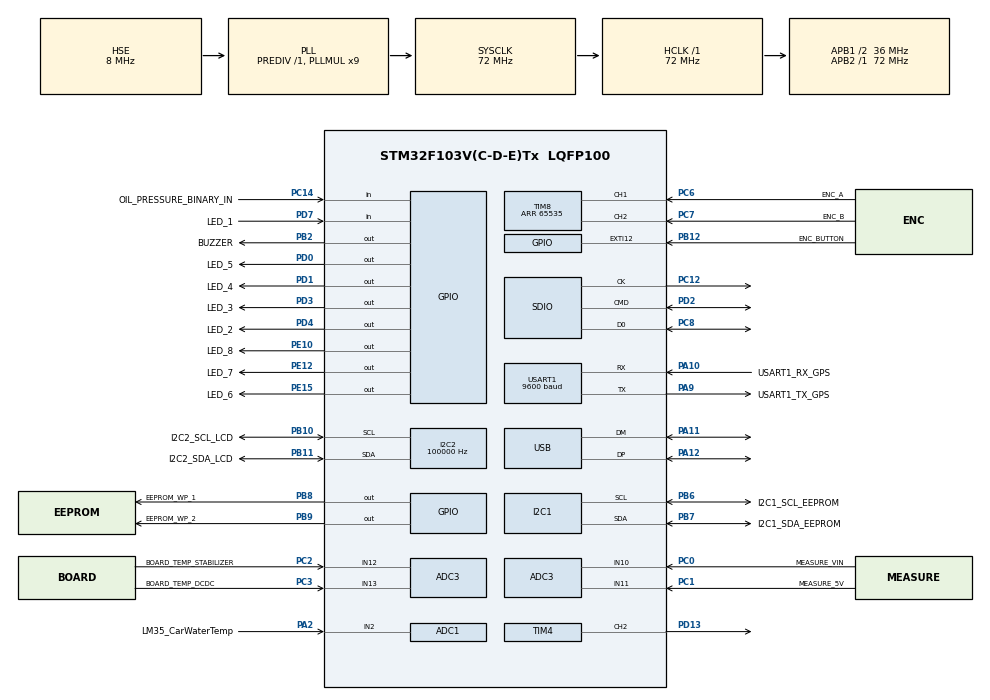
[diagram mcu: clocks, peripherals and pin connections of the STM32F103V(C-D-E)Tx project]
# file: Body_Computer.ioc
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ADC1.Channel-0\#ChannelRegularConversion=ADC_CHANNEL_2
ADC1.ContinuousConvMode=ENABLE
ADC1.NbrOfConversion=1
ADC1.NbrOfConversionFlag=1
ADC1.Rank-0\#ChannelRegularConversion=1
ADC1.SamplingTime-0\#ChannelRegularConversion=ADC_SAMPLETIME_239CYCLES_5
ADC1.master=1
ADC3.Channel-6\#ChannelRegularConversion=ADC_CHANNEL_10
ADC3.Channel-7\#ChannelRegularConversion=ADC_CHANNEL_11
ADC3.Channel-8\#ChannelRegularConversion=ADC_CHANNEL_12
ADC3.Channel-9\#ChannelRegularConversion=ADC_CHANNEL_13
ADC3.ContinuousConvMode=ENABLE
ADC3.DiscontinuousConvMode=DISABLE
ADC3.EnableRegularConversion=ENABLE
ADC3.NbrOfConversion=4
ADC3.NbrOfConversionFlag=1
ADC3.Rank-6\#ChannelRegularConversion=1
ADC3.Rank-7\#ChannelRegularConversion=2
ADC3.Rank-8\#ChannelRegularConversion=3
ADC3.Rank-9\#ChannelRegularConversion=4
ADC3.SamplingTime-6\#ChannelRegularConversion=ADC_SAMPLETIME_239CYCLES_5
ADC3.SamplingTime-7\#ChannelRegularConversion=ADC_SAMPLETIME_239CYCLES_5
ADC3.SamplingTime-8\#ChannelRegularConversion=ADC_SAMPLETIME_239CYCLES_5
ADC3.SamplingTime-9\#ChannelRegularConversion=ADC_SAMPLETIME_239CYCLES_5
Dma.ADC1.3.Direction=DMA_PERIPH_TO_MEMORY
Dma.ADC1.3.Instance=DMA1_Channel1
Dma.ADC1.3.MemDataAlignment=DMA_MDATAALIGN_HALFWORD
Dma.ADC1.3.MemInc=DMA_MINC_ENABLE
Dma.ADC1.3.Mode=DMA_CIRCULAR
Dma.ADC1.3.PeriphDataAlignment=DMA_PDATAALIGN_HALFWORD
Dma.ADC1.3.PeriphInc=DMA_PINC_DISABLE
Dma.ADC1.3.Priority=DMA_PRIORITY_LOW
Dma.ADC3.1.Direction=DMA_PERIPH_TO_MEMORY
Dma.ADC3.1.Instance=DMA2_Channel5
Dma.ADC3.1.MemDataAlignment=DMA_MDATAALIGN_HALFWORD
Dma.ADC3.1.MemInc=DMA_MINC_ENABLE
Dma.ADC3.1.Mode=DMA_CIRCULAR
Dma.ADC3.1.PeriphDataAlignment=DMA_PDATAALIGN_HALFWORD
Dma.ADC3.1.PeriphInc=DMA_PINC_DISABLE
Dma.ADC3.1.Priority=DMA_PRIORITY_LOW
Dma.I2C2_RX.2.Direction=DMA_PERIPH_TO_MEMORY
Dma.I2C2_RX.2.Instance=DMA1_Channel5
Dma.I2C2_RX.2.MemDataAlignment=DMA_MDATAALIGN_BYTE
Dma.I2C2_RX.2.MemInc=DMA_MINC_ENABLE
Dma.I2C2_RX.2.Mode=DMA_NORMAL
Dma.I2C2_RX.2.PeriphDataAlignment=DMA_PDATAALIGN_BYTE
Dma.I2C2_RX.2.PeriphInc=DMA_PINC_DISABLE
Dma.I2C2_RX.2.Priority=DMA_PRIORITY_LOW
Dma.I2C2_TX.0.Direction=DMA_MEMORY_TO_PERIPH
Dma.I2C2_TX.0.Instance=DMA1_Channel4
Dma.I2C2_TX.0.MemDataAlignment=DMA_MDATAALIGN_BYTE
Dma.I2C2_TX.0.MemInc=DMA_MINC_ENABLE
Dma.I2C2_TX.0.Mode=DMA_NORMAL
Dma.I2C2_TX.0.PeriphDataAlignment=DMA_PDATAALIGN_BYTE
Dma.I2C2_TX.0.PeriphInc=DMA_PINC_DISABLE
Dma.I2C2_TX.0.Priority=DMA_PRIORITY_LOW
Dma.Request0=I2C2_TX
Dma.Request1=ADC3
Dma.Request2=I2C2_RX
Dma.Request3=ADC1
FREERTOS.INCLUDE_uxTaskGetStackHighWaterMark=0
FREERTOS.INCLUDE_vTaskDelay=1
FREERTOS.INCLUDE_vTaskDelayUntil=1
FREERTOS.Queues01=Queue_EEPROM_read,5,EEPROM_data_struct,0,Dynamic,NULL,NULL;Queue_EEPROM_write,5,EEPROM_data_struct,0,Dynamic,NULL,NULL;Queue_error_snapshot_dump,5,Error_Code,0,Dynamic,NULL,NULL;Queue_diagnostic_snapshot_dump,5,Diagnostic_Snapshot_struct,0,Dynamic,NULL,NULL
FREERTOS.Tasks01=My_1000ms_Task,0,256,StartTask1000ms,Default,NULL,Dynamic,NULL,NULL;My_500ms_Task,0,128,StartTask500ms,Default,NULL,Dynamic,NULL,NULL;My_LCD_Task,0,512,StartTaskLCD,As external,NULL,Dynamic,NULL,NULL;My_GPS_Task,0,128,StartTaskGPS,As external,NULL,Dynamic,NULL,NULL;My_EEPROM_Task,2,128,StartTaskEEPROM,As external,NULL,Dynamic,NULL,NULL;My_DumpToEEPROM,-1,128,StartTaskDumpToEEPROM,As external,NULL,Dynamic,NULL,NULL;My_DumpToSDCard,-1,1024,StartTaskDumpToSDCard,Default,NULL,Dynamic,NULL,NULL;My_250ms_Task,-3,512,StartTask250ms,Default,NULL,Dynamic,NULL,NULL;My_50ms_Task,-3,128,StartTask50ms,Default,NULL,Dynamic,NULL,NULL;My_DiagCheck,1,256,StartTaskDiagCheck,As external,NULL,Dynamic,NULL,NULL;my_AlarmControl,-3,256,StartTaskAlarmControl,As external,NULL,Dynamic,NULL,NULL
FREERTOS.Timers01=My_Timer_ENC_Button,ENC_Button_LongPress_Callback,osTimerOnce,Default,NULL,Dynamic,NULL;My_Timer_carWaterTempValueCheck,Timer_carWaterTempValueCheck,osTimerOnce,As external,NULL,Dynamic,NULL;My_Timer_carOilTempValueCheck,Timer_carOilTempValueCheck,osTimerOnce,As external,NULL,Dynamic,NULL;My_Timer_carOilAnalogPressureValueCheck,Timer_carOilAnalogPressureValueCheck,osTimerOnce,As external,NULL,Dynamic,NULL;My_Timer_carMainBattVoltageValueCheck,Timer_carMainBattVoltageValueCheck,osTimerOnce,As external,NULL,Dynamic,NULL;My_Timer_carAuxBattVoltageValueCheck,Timer_carAuxBattVoltageValueCheck,osTimerOnce,As external,NULL,Dynamic,NULL;My_Timer_carFuelLevelValueCheck,Timer_carFuelLevelValueCheck,osTimerOnce,As external,NULL,Dynamic,NULL;My_Timer_board3V3VoltageValueCheck,Timer_board3V3VoltageValueCheck,osTimerOnce,As external,NULL,Dynamic,NULL;My_Timer_board5VVoltageValueCheck,Timer_board5VVoltageValueCheck,osTimerOnce,As external,NULL,Dynamic,NULL;My_Timer_boardVinVoltageValueCheck,Timer_boardVinVoltageValueCheck,osTimerOnce,As external,NULL,Dynamic,NULL;My_Timer_board3V3TempValueCheck,Timer_board3V3TempValueCheck,osTimerOnce,As external,NULL,Dynamic,NULL;My_Timer_board5VTempValueCheck,Timer_board5VTempValueCheck,osTimerOnce,As external,NULL,Dynamic,NULL;My_Timer_carOilBinaryPressureValueCheck,Timer_carOilBinaryPressureValueCheck,osTimerOnce,As external,NULL,Dynamic,NULL;My_Timer_Buzzer,Timer_Buzzer,osTimerOnce,As external,NULL,Dynamic,NULL
FREERTOS.configCHECK_FOR_STACK_OVERFLOW=1
FREERTOS.configENABLE_BACKWARD_COMPATIBILITY=0
FREERTOS.configGENERATE_RUN_TIME_STATS=1
FREERTOS.configMAX_PRIORITIES=7
FREERTOS.configRECORD_STACK_HIGH_ADDRESS=1
FREERTOS.configTIMER_QUEUE_LENGTH=40
FREERTOS.configTIMER_TASK_STACK_DEPTH=256
FREERTOS.configTOTAL_HEAP_SIZE=20480
FREERTOS.configUSE_MALLOC_FAILED_HOOK=1
FREERTOS.configUSE_PREEMPTION=1
FREERTOS.configUSE_STATS_FORMATTING_FUNCTIONS=1
FREERTOS.configUSE_TIMERS=1
FREERTOS.configUSE_TRACE_FACILITY=1
I2C1.I2C_Mode=I2C_Standard
I2C1.NoStretchMode=I2C_NOSTRETCH_DISABLE
I2C2.AddressingMode=I2C_ADDRESSINGMODE_7BIT
I2C2.ClockSpeed=100000
I2C2.I2C_Mode=I2C_Standard
Mcu.Family=STM32F1
Mcu.Name=STM32F103V(C-D-E)Tx
Mcu.Package=LQFP100
NVIC.DMA1_Channel1_IRQn=true\:5\:0\:false\:false\:true\:true\:false\:true
NVIC.DMA1_Channel4_IRQn=true\:5\:0\:true\:false\:true\:true\:false\:true
NVIC.DMA1_Channel5_IRQn=true\:5\:0\:true\:false\:true\:true\:false\:true
NVIC.DMA2_Channel4_5_IRQn=true\:5\:0\:false\:false\:true\:true\:false\:true
NVIC.EXTI15_10_IRQn=true\:5\:0\:false\:false\:true\:true\:true\:true
NVIC.I2C1_ER_IRQn=true\:5\:0\:false\:false\:true\:true\:true\:true
NVIC.I2C1_EV_IRQn=true\:5\:0\:false\:false\:true\:true\:true\:true
NVIC.I2C2_ER_IRQn=true\:6\:0\:true\:false\:true\:true\:true\:true
NVIC.I2C2_EV_IRQn=true\:6\:0\:true\:false\:true\:true\:true\:true
NVIC.PriorityGroup=NVIC_PRIORITYGROUP_4
NVIC.TIM6_IRQn=true\:0\:0\:false\:false\:true\:false\:false\:true
NVIC.TIM7_IRQn=true\:5\:0\:false\:false\:true\:true\:true\:true
NVIC.TimeBase=TIM6_IRQn
NVIC.TimeBaseIP=TIM6
NVIC.USART1_IRQn=true\:5\:0\:true\:false\:true\:true\:true\:true
NVIC.USB_LP_CAN1_RX0_IRQn=true\:5\:0\:false\:false\:true\:true\:false\:true
OSC_IN.Mode=HSE-External-Oscillator
OSC_IN.Signal=RCC_OSC_IN
OSC_OUT.Mode=HSE-External-Oscillator
OSC_OUT.Signal=RCC_OSC_OUT
PA10.GPIO_Label=USART1_RX_GPS
PA10.Mode=Asynchronous
PA10.Signal=USART1_RX
PA11.Mode=Device
PA11.Signal=USB_DM
PA12.Mode=Device
PA12.Signal=USB_DP
PA13.Mode=Trace_Asynchronous_SW
PA13.Signal=SYS_JTMS-SWDIO
PA14.Mode=Trace_Asynchronous_SW
PA14.Signal=SYS_JTCK-SWCLK
PA2.GPIO_Label=LM35_CarWaterTemp
PA2.Signal=ADCx_IN2
PA9.GPIO_Label=USART1_TX_GPS
PA9.Mode=Asynchronous
PA9.Signal=USART1_TX
PB10.GPIO_Label=I2C2_SCL_LCD
PB10.Mode=I2C
PB10.Signal=I2C2_SCL
PB11.GPIO_Label=I2C2_SDA_LCD
PB11.Mode=I2C
PB11.Signal=I2C2_SDA
PB12.GPIO_Label=ENC_BUTTON
PB12.GPIO_ModeDefaultEXTI=GPIO_MODE_IT_FALLING
PB12.GPIO_PuPd=GPIO_NOPULL
PB12.Signal=GPXTI12
PB2.GPIO_Label=BUZZER
PB2.GPIO_PuPd=GPIO_PULLDOWN
PB2.Signal=GPIO_Output
PB3.GPIO_Label=SWO
PB3.Mode=Trace_Asynchronous_SW
PB3.Signal=SYS_JTDO-TRACESWO
PB6.GPIO_Label=I2C1_SCL_EEPROM
PB6.Mode=I2C
PB6.Signal=I2C1_SCL
PB7.GPIO_Label=I2C1_SDA_EEPROM
PB7.Mode=I2C
PB7.Signal=I2C1_SDA
PB8.GPIO_Label=EEPROM_WP_1
PB8.GPIO_PuPd=GPIO_PULLDOWN
PB8.Signal=GPIO_Output
PB9.GPIO_Label=EEPROM_WP_2
PB9.GPIO_PuPd=GPIO_PULLDOWN
PB9.Signal=GPIO_Output
PC0.GPIO_Label=MEASURE_VIN
PC0.Signal=ADCx_IN10
PC1.GPIO_Label=MEASURE_5V
PC1.Signal=ADCx_IN11
PC12.Mode=SD_1_bit
PC12.Signal=SDIO_CK
PC14-OSC32_IN.GPIO_Label=OIL_PRESSURE_BINARY_IN
PC14-OSC32_IN.Signal=GPIO_Input
PC2.GPIO_Label=BOARD_TEMP_STABILIZER
PC2.Signal=ADCx_IN12
PC3.GPIO_Label=BOARD_TEMP_DCDC
PC3.Signal=ADCx_IN13
PC6.GPIO_Label=ENC_A
PC6.Signal=S_TIM8_CH1
PC7.GPIO_Label=ENC_B
PC7.Signal=S_TIM8_CH2
PC8.Mode=SD_1_bit
PC8.Signal=SDIO_D0
PD0.GPIO_Label=LED_5
PD0.Signal=GPIO_Output
PD1.GPIO_Label=LED_4
PD1.Signal=GPIO_Output
PD13.Signal=S_TIM4_CH2
PD2.Mode=SD_1_bit
PD2.Signal=SDIO_CMD
PD3.GPIO_Label=LED_3
PD3.Signal=GPIO_Output
PD4.GPIO_Label=LED_2
PD4.Signal=GPIO_Output
PD7.GPIO_Label=LED_1
PD7.Signal=GPIO_Input
PE10.GPIO_Label=LED_8
PE10.Signal=GPIO_Output
PE12.GPIO_Label=LED_7
PE12.Signal=GPIO_Output
PE15.GPIO_Label=LED_6
PE15.Signal=GPIO_Output
ProjectManager.HeapSize=0x400
ProjectManager.StackSize=0x2000
ProjectManager.TargetToolchain=STM32CubeIDE
RCC.ADCPresc=RCC_ADCPCLK2_DIV6
RCC.AHBFreq_Value=72000000
RCC.APB1CLKDivider=RCC_HCLK_DIV2
RCC.APB1Freq_Value=36000000
RCC.APB1TimFreq_Value=72000000
RCC.APB2Freq_Value=72000000
RCC.APB2TimFreq_Value=72000000
RCC.HCLKFreq_Value=72000000
RCC.PLLMUL=RCC_PLL_MUL9
RCC.PLLSourceVirtual=RCC_PLLSOURCE_HSE
RCC.SYSCLKFreq_VALUE=72000000
RCC.SYSCLKSource=RCC_SYSCLKSOURCE_PLLCLK
RCC.USBFreq_Value=48000000
RCC.USBPrescaler=RCC_USBCLKSOURCE_PLL_DIV1_5
SDIO.ClockDiv=18
SH.ADCx_IN10.0=ADC3_IN10,IN10
SH.ADCx_IN11.0=ADC3_IN11,IN11
SH.ADCx_IN12.0=ADC3_IN12,IN12
SH.ADCx_IN13.0=ADC3_IN13,IN13
SH.ADCx_IN2.0=ADC1_IN2,IN2
SH.S_TIM4_CH2.0=TIM4_CH2,PWM Generation2 CH2
SH.S_TIM8_CH1.0=TIM8_CH1,Encoder_Interface
SH.S_TIM8_CH2.0=TIM8_CH2,Encoder_Interface
TIM4.Channel-PWM\ Generation2\ CH2=TIM_CHANNEL_2
TIM4.Period=49
TIM4.Prescaler=71
TIM7.AutoReloadPreload=TIM_AUTORELOAD_PRELOAD_DISABLE
TIM7.Period=99
TIM7.Prescaler=71
TIM8.ClockDivision=TIM_CLOCKDIVISION_DIV1
TIM8.EncoderMode=TIM_ENCODERMODE_TI12
TIM8.IC1Filter=15
TIM8.IC1Prescaler=TIM_ICPSC_DIV1
TIM8.IC2Filter=15
TIM8.IC2Prescaler=TIM_ICPSC_DIV1
TIM8.Period=65535
USART1.BaudRate=9600
USART1.VirtualMode=VM_ASYNC
USB_DEVICE.CLASS_NAME_FS=MSC
USB_DEVICE.USBD_MAX_NUM_CONFIGURATION=2
USB_DEVICE.USBD_MAX_NUM_INTERFACES=2
USB_DEVICE.USBD_SELF_POWERED=0
USB_DEVICE.VirtualMode=Msc
USB_DEVICE.VirtualModeFS=Msc_FS
VP_FATFS_VS_SDIO.Mode=SDIO
VP_FREERTOS_VS_CMSIS_V1.Mode=CMSIS_V1
VP_SYS_VS_tim6.Mode=TIM6
VP_TIM7_VS_ClockSourceINT.Mode=Enable_Timer
VP_USB_DEVICE_VS_USB_DEVICE_MSC_FS.Mode=MSC_FS
board=custom

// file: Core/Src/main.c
/* USER CODE BEGIN Header */
/**
  ******************************************************************************
  * @file           : main.c
  * @brief          : Main program body
  ******************************************************************************
  * @attention
  *
  * <h2><center>&copy; Copyright (c) 2020 STMicroelectronics.
  * All rights reserved.</center></h2>
  *
  * This software component is licensed by ST under BSD 3-Clause license,
  * the "License"; You may not use this file except in compliance with the
  * License. You may obtain a copy of the License at:
  *                        opensource.org/licenses/BSD-3-Clause
  *
  ******************************************************************************
  */
/* USER CODE END Header */
#include "main.h"
#include "cmsis_os.h"
#include "adc.h"
#include "dma.h"
#include "fatfs.h"
#include "i2c.h"
#include "sdio.h"
#include "tim.h"
#include "usart.h"
#include "usb_device.h"
#include "gpio.h"

/* USER CODE BEGIN Includes */

#include "../GPS/GPS_Parsing.h"
#include "../I2C_Workaround/I2C_Workaround.h"
#include "Init_Functions.h"

/* USER CODE END Includes */

/* USER CODE BEGIN PV */
volatile uint32_t licznikShortPresses = 0;
extern ENCButton_struct ENC_button;
extern uint16_t ADC1Measures[NO_OF_ADC1_MEASURES];
extern uint16_t ADC3Measures[NO_OF_ADC3_MEASURES];
extern GPS_data_struct GPS;
//extern LCD_parameters_struct LCD;
extern uint32_t Tim7_Counter_100us;
extern osTimerId My_Timer_ENC_ButtonHandle;

/* USER CODE END PV */

void SystemClock_Config(void);
void MX_FREERTOS_Init(void);
/* USER CODE BEGIN PFP */

void HAL_UART_RxCpltCallback(UART_HandleTypeDef *huart);
void HAL_GPIO_EXTI_Callback(uint16_t GPIO_Pin);

/* USER CODE END PFP */

int main(void)
{
  /* USER CODE BEGIN 1 */
	Error_Code error = NO_ERROR;
  /* USER CODE END 1 */

  /* MCU Configuration--------------------------------------------------------*/

  /* Reset of all peripherals, Initializes the Flash interface and the Systick. */
  HAL_Init();

  /* Configure the system clock */
  SystemClock_Config();

  /* Initialize all configured peripherals */
  MX_GPIO_Init();
  MX_DMA_Init();
  MX_I2C2_Init();
  MX_TIM8_Init();
  MX_ADC3_Init();
  MX_USART1_UART_Init();
  MX_TIM7_Init();
  MX_I2C1_Init();
  MX_TIM4_Init();
  MX_ADC1_Init();
  MX_SDIO_SD_Init();
  MX_FATFS_Init();
  /* USER CODE BEGIN 2 */

  	error = (Error_Code)HAL_TIM_Encoder_Start(&htim8, TIM_CHANNEL_ALL);

	if(NO_ERROR != error)
	{
		error = TIM__ENCODER_START_FAIL;
		my_error_handler(error);
	}

	error = (Error_Code)HAL_ADCEx_Calibration_Start(&hadc1);
	error = (Error_Code)HAL_ADCEx_Calibration_Start(&hadc3);

	if(NO_ERROR != error)
	{
		error = ADC__CALIBRATION_FAIL;
		my_error_handler(error);
	}

	HAL_ADC_Start_DMA(&hadc1, (uint32_t*)ADC1Measures, NO_OF_ADC1_MEASURES);
	HAL_ADC_Start_DMA(&hadc3, (uint32_t*)ADC3Measures, NO_OF_ADC3_MEASURES);

	error = (Error_Code)HAL_TIM_PWM_Start(&htim4, TIM_CHANNEL_2);

	if(NO_ERROR != error)
	{
		error = TIM__PWM_START_FAIL;
		my_error_handler(error);
	}

	HAL_Delay(300);

  /* * * * * * * * * * * * * * * * * * * * * * * * * * * * * * * * * * * * */
  /** !!!!TURNING THIS ON WILL ERASE WHOLE EEPROMS!!!! **/
#if 0
  error = EraseWholeEEPROM(&EEPROM_car);
	if(NO_ERROR != error)
	{
		error = EEPROM__WHOLE_MEMORY_ERASE_FAIL;
		my_error_handler(error);
	}
#endif

#if 0
  error = EraseWholeEEPROM(&EEPROM_board);
	if(NO_ERROR != error)
	{
		error = EEPROM__WHOLE_MEMORY_ERASE_FAIL;
		my_error_handler(error);
	}
#endif
  /* * * * * * * * * * * * * * * * * * * * * * * * * * * * * * * * * * * * */

  /* USER CODE END 2 */

  /* Call init function for freertos objects (in freertos.c) */
  MX_FREERTOS_Init();
  /* Start scheduler */
  osKernelStart();

  /* We should never get here as control is now taken by the scheduler */
  /* Infinite loop */
  /* USER CODE BEGIN WHILE */
  while (1)
  {
		error = OS__MAIN_WHILE_LOOP_REACHED;
		my_error_handler(error);
    /* USER CODE END WHILE */

  }
}

void SystemClock_Config(void)
{
  RCC_OscInitTypeDef RCC_OscInitStruct = {0};
  RCC_ClkInitTypeDef RCC_ClkInitStruct = {0};
  RCC_PeriphCLKInitTypeDef PeriphClkInit = {0};

  /** Initializes the RCC Oscillators according to the specified parameters
  * in the RCC_OscInitTypeDef structure.
  */
  RCC_OscInitStruct.OscillatorType = RCC_OSCILLATORTYPE_HSE;
  RCC_OscInitStruct.HSEState = RCC_HSE_ON;
  RCC_OscInitStruct.HSEPredivValue = RCC_HSE_PREDIV_DIV1;
  RCC_OscInitStruct.HSIState = RCC_HSI_ON;
  RCC_OscInitStruct.PLL.PLLState = RCC_PLL_ON;
  RCC_OscInitStruct.PLL.PLLSource = RCC_PLLSOURCE_HSE;
  RCC_OscInitStruct.PLL.PLLMUL = RCC_PLL_MUL9;
  if (HAL_RCC_OscConfig(&RCC_OscInitStruct) != HAL_OK)
  {
    Error_Handler();
  }
  /** Initializes the CPU, AHB and APB buses clocks
  */
  RCC_ClkInitStruct.ClockType = RCC_CLOCKTYPE_HCLK|RCC_CLOCKTYPE_SYSCLK
                              |RCC_CLOCKTYPE_PCLK1|RCC_CLOCKTYPE_PCLK2;
  RCC_ClkInitStruct.SYSCLKSource = RCC_SYSCLKSOURCE_PLLCLK;
  RCC_ClkInitStruct.AHBCLKDivider = RCC_SYSCLK_DIV1;
  RCC_ClkInitStruct.APB1CLKDivider = RCC_HCLK_DIV2;
  RCC_ClkInitStruct.APB2CLKDivider = RCC_HCLK_DIV1;

  if (HAL_RCC_ClockConfig(&RCC_ClkInitStruct, FLASH_LATENCY_2) != HAL_OK)
  {
    Error_Handler();
  }
  PeriphClkInit.PeriphClockSelection = RCC_PERIPHCLK_ADC|RCC_PERIPHCLK_USB;
  PeriphClkInit.AdcClockSelection = RCC_ADCPCLK2_DIV6;
  PeriphClkInit.UsbClockSelection = RCC_USBCLKSOURCE_PLL_DIV1_5;
  if (HAL_RCCEx_PeriphCLKConfig(&PeriphClkInit) != HAL_OK)
  {
    Error_Handler();
  }
}

/* USER CODE BEGIN 4 */

/* UART communication via Interrupts handling */
void HAL_UART_RxCpltCallback(UART_HandleTypeDef *huart)
{
	static uint8_t counter = 0;
	static uint8_t nCounter = 0;
	static uint8_t rCounter = 0;
	static uint8_t dataStarted = 0;		/* Set when "$" (so the first sign in the string) is found and Reset when string ends (after second \n\r */

#ifdef GPS_RECEIVING
	/* Checking if interrupt is from UART1 (GPS) */
	if(&huart1 == huart)
	{
		if(FALSE == GPS.DataReady)
		{
			if('$' == GPS.receivedByte)
				dataStarted = TRUE;

			if(TRUE == dataStarted)
			{
				if('\r' == GPS.receivedByte)
				{
					++rCounter;
						GPS.GPS_buffer[counter] = GPS.receivedByte;
						++counter;
				}
				else
				{
					if('\n' == GPS.receivedByte)
					{
						++nCounter;
							GPS.GPS_buffer[counter] = GPS.receivedByte;
							++counter;
					}
					else
					{
						if(((2 > rCounter) || (2 > nCounter)) &&  (GPS_BUFFER_SIZE > counter))
						{
							GPS.GPS_buffer[counter] = GPS.receivedByte;
							++counter;
						}
						else
						{
							GPS.DataReady = TRUE;
							counter = 0;
							rCounter = 0;
							nCounter = 0;
							dataStarted = FALSE;
						}//if((2 > rCounter) || (2 > nCounter))
					}//if('\n' == GPS.receivedByte)
				}//if('\r' == GPS.receivedByte)
			}//if(TRUE == dataStarted)
		}//if(FALSE == GPS.DataReady)

		HAL_UART_Receive_IT(&huart1, (uint8_t *)(&GPS.receivedByte), 1u);
	}//if(&huart1 == *huart)
#endif
}

void HAL_GPIO_EXTI_Callback(uint16_t GPIO_Pin)
{
	static uint32_t lastTimerCounter = 0;
	Error_Code error = NO_ERROR;

	/* Checking if interrupt is from ENC_BUTTON pin */
	if(ENC_BUTTON_Pin == GPIO_Pin)
	{
		if((Tim7_Counter_100us - lastTimerCounter) > (DEBOUNCING_TIME_FOR_ENCODER_BUTTON * 10U) /*ms*/)
		{
			if(GPIO_PIN_SET == HAL_GPIO_ReadPin(ENC_BUTTON_GPIO_Port, ENC_BUTTON_Pin))	/*Button Pushed In*/
			{
				error = (Error_Code)osTimerStart(My_Timer_ENC_ButtonHandle, ENC_BUTTON_LONG_PRESS_TIME);
				if(NO_ERROR != error)
				{
					error = OS__STARTING_TIMER_FAILED;
					my_error_handler(error);
				}
			}
			else	/*Button Released*/
			{
				if(FALSE == ENC_button.longPressInfoForISR)	/* If long press was NOT detected then it is a short press */
				{
					error = (Error_Code)osTimerStop(My_Timer_ENC_ButtonHandle);	/* Stop the timer */
					if(NO_ERROR != error)
					{
						error = OS__STOPPING_TIMER_FAILED;
						my_error_handler(error);
					}
					ENC_button.allFlags = 0b00001001;	/* shortPressDetected and shortPressDetectedBuzzer set to 1 */
					HAL_GPIO_TogglePin(LED_7_GPIO_Port, LED_7_Pin);
					++licznikShortPresses;
				}
				else	/* Long press was detected so do not set short press and reset the flag for ISR for the next time */
				{
					ENC_button.longPressInfoForISR = FALSE;
				}

			}
			lastTimerCounter = Tim7_Counter_100us;
		}
	}
}

/* USER CODE END 4 */

 /**
  * @brief  Period elapsed callback in non blocking mode
  * @note   This function is called  when TIM6 interrupt took place, inside
  * HAL_TIM_IRQHandler(). It makes a direct call to HAL_IncTick() to increment
  * a global variable "uwTick" used as application time base.
  * @param  htim : TIM handle
  * @retval None
  */
void HAL_TIM_PeriodElapsedCallback(TIM_HandleTypeDef *htim)
{
  if (htim->Instance == TIM6) {
    HAL_IncTick();
  }
  /* USER CODE BEGIN Callback 1 */
#ifdef RUNTIME_STATS_TIMER_CONFIG
  if (&htim7 == htim)
  {
	  ++Tim7_Counter_100us;
  }
#endif
  /* USER CODE END Callback 1 */
}

void Error_Handler(void)
{
  /* USER CODE BEGIN Error_Handler_Debug */
  /* User can add his own implementation to report the HAL error return state */
	my_error_handler(UNKNOWN_ERROR);

  /* USER CODE END Error_Handler_Debug */
}

/************************ (C) COPYRIGHT STMicroelectronics *****END OF FILE****/

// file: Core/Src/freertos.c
/* USER CODE BEGIN Header */
/**
 ******************************************************************************
 * File Name          : freertos.c
 * Description        : Code for freertos applications
 * Author			  : Wojciech Grzelinski
 ******************************************************************************
 * Copyright (c) 2020 STMicroelectronics.
 * All rights reserved.</center></h2>
 *
 * This software component is licensed by ST under Ultimate Liberty license
 * SLA0044, the "License"; You may not use this file except in compliance with
 * the License. You may obtain a copy of the License at:
 *                             www.st.com/SLA0044
 *
 ******************************************************************************
 */
/* USER CODE END Header */

#include "FreeRTOS.h"
#include "task.h"
#include "main.h"
#include "cmsis_os.h"

/* USER CODE BEGIN Includes */

#include "../VariousFunctions/Functions.h"
#include "../GPS/GPS_Parsing.h"
#include "../EEPROM/EEPROM.h"
#include "Init_Functions.h"

#include "fatfs.h"
#include "sdio.h"

/* USER CODE END Includes */

/* USER CODE BEGIN PD */
uint8_t tuBylemFLAG = 0;
uint8_t TEMPBUFF[100];
/* USER CODE END PD */

/* USER CODE BEGIN Variables */
/* * * * * * * * * * * * * * * * * * * * * * * * * * * * * * * * * * * * */
extern I2C_HandleTypeDef hi2c1;
extern TIM_HandleTypeDef htim8;
extern SD_HandleTypeDef hsd;

#ifdef RUNTIME_STATS_TIMER_CONFIG
extern TIM_HandleTypeDef htim7;
#endif

/* Handlers for SD Memory Card usage (TASK: My_DumpToSDCard) */
extern FIL SDFile;
extern FATFS SDFatFS;
/* * * * * * * * * * * * * * * * * * * * * * * * * * * * * * * * * * * * */

/* * * * * * * * * * * * * * * * * * * * * * * * * * * * * * * * * * * * */
/* For debugging - task time etc. */
volatile uint32_t Tim7_Counter_100us;

/* For Signaling ENC button and scroll */
volatile ENCButton_struct ENC_button = {0};
volatile int8_t EncoderCounterDiff = 0;

/* For measurements from ADC3 */
volatile uint16_t ADC1Measures[NO_OF_ADC1_MEASURES] = { 0 };
volatile uint16_t ADC3Measures[NO_OF_ADC3_MEASURES] = { 0 };

/* For GPS data, buffering, messages for LCD */
GPS_data_struct GPS =
{ //.TimeZoneAdjPoland = 2,/* .homeLatitude = 52.093731, .homeLongitude = 20.661411,*/
.forLCD.hours.messageReadyFLAG = FALSE,
.forLCD.minutes.messageReadyFLAG = FALSE,
.forLCD.seconds.messageReadyFLAG = FALSE,
.forLCD.clock.messageReadyFLAG = FALSE,
.forLCD.latitude.messageReadyFLAG = FALSE,
.forLCD.latitudeIndicator.messageReadyFLAG = FALSE,
.forLCD.longitude.messageReadyFLAG = FALSE,
.forLCD.longitudeIndicator.messageReadyFLAG = FALSE,
.forLCD.status.messageReadyFLAG = FALSE,
.forLCD.satellitesUsed.messageReadyFLAG = FALSE,
.forLCD.altitude.messageReadyFLAG = FALSE,
.forLCD.speed.messageReadyFLAG = FALSE };

/* * * * * * * * * * * * * * * * * * * * * * * * * * * * * * * * * * * * */
/* For LCD parameters and settings */
LCD_parameters_struct LCD =
{ .addressLCD = 0x27, .noOfRowsLCD = NO_OF_ROWS_IN_LCD, .noOfColumnsLCD = NO_OF_COLUMNS_IN_LCD };

/* * * * * * * * * * * * * * * * * * * * * * * * * * * * * * * * * * * * */
/* For measuring Board temperatures with usage of NTC parameters */
NTC_parameters_struct NTC =
		{ .Beta = 4250, .R25 = 100000, .Rgnd = 10000, .T25 = 298, .beta_x_T25 =
				1266500 };

/* * * * * * * * * * * * * * * * * * * * * * * * * * * * * * * * * * * * */
/* Counter for CAR EEPROM */
CAR_EEPROM_counters_struct CAR_EEPROM_counters = {0};

/* For CAR EEPROM usage, its addressing and blocking */
EEPROM_parameters_struct EEPROM_car =
{ .EEPROM_hi2c = &hi2c1, .address = EEPROM_CAR_ADDRESS, .pin =
		EEPROM_CAR_BLOCK_PIN, .port = EEPROM_CAR_BLOCK_PORT };

/* CAR SETTINGS and VALUES*/
CAR_mileage_struct CAR_mileage = {0};
LCD_message totalMileageForLCD = {.messageHandler = NULL, .size = 0, .messageReadyFLAG = 0};
LCD_message tripMileageForLCD = {.messageHandler = NULL, .size = 0, .messageReadyFLAG = 0};

waterTempSettings_struct CAR_waterTemp = {0};
carTemperature_type waterTemperatureValue = 0.0;
LCD_message waterTemperatureValueForLCD = {.messageHandler = NULL, .size = 0, .messageReadyFLAG = 0};

oilTempSettings_struct CAR_oilTemp = {0};
carTemperature_type oilTemperatureValue = 0.0;
LCD_message oilTemperatureValueForLCD = {.messageHandler = NULL, .size = 0, .messageReadyFLAG = 0};

oilPressureSettings_struct CAR_oilPressure = {0};
#ifdef OIL_PRESSURE_ANALOG_SENSOR
carOilAnalogPressure_type oilPressureValue = 0.0;
LCD_message oilPressureValueForLCD = {.messageHandler = NULL, .size = 0, .messageReadyFLAG = 0};
#endif
#ifdef OIL_PRESSURE_BINARY_SENSOR
carOilBinaryPressure_type oilPressureValueBinary = NOK;
LCD_message oilPressureValueBinaryForLCD = {.messageHandler = NULL, .size = 0, .messageReadyFLAG = 0};
#endif

batterySettings_struct CAR_mainBattery = {0};
carVoltage_type mainBatteryVoltageValue = 0.0;
LCD_message mainBatteryVoltageValueForLCD = {.messageHandler = NULL, .size = 0, .messageReadyFLAG = 0};

batterySettings_struct CAR_auxiliaryBattery = {0};
carVoltage_type auxiliaryBatteryVoltageValue = 0.0;
LCD_message auxiliaryBatteryVoltageValueForLCD = {.messageHandler = NULL, .size = 0, .messageReadyFLAG = 0};

fuelSettings_struct CAR_fuel = {0};
cafFuelLevel_type fuelLevelValue = 0.0;
LCD_message fuelLevelValueForLCD = {.messageHandler = NULL, .size = 0, .messageReadyFLAG = 0};
/* * * * * * * * * * * * * * * * * * * * * * * * * * * * * * * * * * * * */

/* * * * * * * * * * * * * * * * * * * * * * * * * * * * * * * * * * * * */
/* Counters for BOARD EEPROM */
BOARD_EEPROM_counters_struct BOARD_EEPROM_counters = {0};

/* For BOARD EEPROM usage, its addressing and blocking */
EEPROM_parameters_struct EEPROM_board =
{ .EEPROM_hi2c = &hi2c1, .address = EEPROM_BOARD_ADDRESS, .pin =
		EEPROM_BOARD_BLOCK_PIN, .port = EEPROM_BOARD_BLOCK_PORT };

/* CAR SETTINGS and VALUES*/
boardVoltagesSettings_struct BOARD_voltage = {0};
boardVoltage_type voltage3V3 = 0.0;
boardVoltage_type voltage5V = 0.0;
boardVoltage_type voltageIn = 0.0;
LCD_message voltage3V3ForLCD = {.messageHandler = NULL, .size = 0, .messageReadyFLAG = 0};
LCD_message voltage5VForLCD = {.messageHandler = NULL, .size = 0, .messageReadyFLAG = 0};
LCD_message voltageInForLCD = {.messageHandler = NULL, .size = 0, .messageReadyFLAG = 0};

boardTemperaturesSettings_struct BOARD_temperature = {0};
boardTemperature_type temperature3V3DCDC = 0.0;
boardTemperature_type temperature5VDCDC = 0.0;
LCD_message temperature3V3DCDCForLCD = {.messageHandler = NULL, .size = 0, .messageReadyFLAG = 0};
LCD_message temperature5VDCDCForLCD = {.messageHandler = NULL, .size = 0, .messageReadyFLAG = 0};

buzzerMainSettings_struct BUZZER_settings = {0};
LCDMainSettings_struct LCD_MainSettings = {0};
/* * * * * * * * * * * * * * * * * * * * * * * * * * * * * * * * * * * * */

/* Car information (Key, Engine status etc.) */
CarStateinfo_type CarStateInfo = {0};

/* * * * * * * * * * * * * * * * * * * * * * * * * * * * * * * * * * * * */
/* Constant value limits and check - hard-coded, to be changed only by recompilation */
GlobalValuesLimits_struct GlobalValuesLimits = {
	.polishTimeAdj_min = 1,
	.polishTimeAdj_max = 2,
	.timeZoneAdj_min = -12,
	.timeZoneAdj_max = 12,

	.waterHighTempWarningThreshold_min	= 50,
	.waterHighTempWarningThreshold_max	= 150,
	.waterHighTempAlarmThreshold_min	= 50,
	.waterHighTempAlarmThreshold_max	= 150,
	.waterHighTempFanOnThreshold_min	= 50,
	.waterHighTempFanOnThreshold_max	= 150,
	.waterHighTempFanOffThreshold_min	= 50,
	.waterHighTempFanOffThreshold_max	= 150,

	.oilHighTempWarningThreshold_min	= 50,
	.oilHighTempWarningThreshold_max	= 150,
	.oilHighTempAlarmThreshold_min		= 50,
	.oilHighTempAlarmThreshold_max		= 150,

	.oilHighPressureAlarmThreshold_min	= 0.1,
	.oilHighPressureAlarmThreshold_max	= 7.5,
	.oilLowPressureAlarmThreshold_min	= 0.1,
	.oilLowPressureAlarmThreshold_max	= 7.5,

	.batteryLowVoltageAlarmThreshold_min	= 8.00,
	.batteryLowVoltageAlarmThreshold_max	= 18.00,
	.batteryHighVoltageAlarmThreshold_min	= 8.00,
	.batteryHighVoltageAlarmThreshold_max	= 18.00,

	.fuelLowLevelWarningThreshold_min	= 5,
	.fuelLowLevelWarningThreshold_max	= 80,

	.board3V3SupplyLowThreshold_min		= 1.80,
	.board3V3SupplyLowThreshold_max		= 4.00,
	.board3V3SupplyHighThreshold_min	= 1.80,
	.board3V3SupplyHighThreshold_max	= 4.00,
	.board5VSupplyLowThreshold_min		= 4.00,
	.board5VSupplyLowThreshold_max		= 6.00,
	.board5VSupplyHighThreshold_min		= 4.00,
	.board5VSupplyHighThreshold_max		= 6.00,
	.boardVinSupplyLowThreshold_min		= 6.00,
	.boardVinSupplyLowThreshold_max		= 17.00,

	.board5VDCDCTemperatureHighThreshold_min	= 20,
	.board5VDCDCTemperatureHighThreshold_max	= 150,
	.board3V3DCDCTemperatureHighThreshold_min	= 20,
	.board3V3DCDCTemperatureHighThreshold_max	= 150,

	.homeScreen_min						= MainMenu_Layer,
	.homeScreen_max						= JarvisInfo_Layer,
	.autoHomeReturnTime_min				= 3,
	.autoHomeReturnTime_max				= 255,
	.backlightLevel_min					= 1,
	.backlightLevel_max					= 10,
	.secondsToAutoTurnOffBacklight_min	= 2,
	.secondsToAutoTurnOffBacklight_max	= 255,
	.autoBacklightOffHourStart_min		= 0,
	.autoBacklightOffHourStart_max		= 24,
	.autoBacklightOffHourEnd_min		= 0,
	.autoBacklightOffHourEnd_max		= 24
};
/* * * * * * * * * * * * * * * * * * * * * * * * * * * * * * * * * * * * */

/* USER CODE END Variables */
osThreadId My_1000ms_TaskHandle;
osThreadId My_500ms_TaskHandle;
osThreadId My_LCD_TaskHandle;
osThreadId My_GPS_TaskHandle;
osThreadId My_EEPROM_TaskHandle;
osThreadId My_DumpToEEPROMHandle;
osThreadId My_DumpToSDCardHandle;
osThreadId My_250ms_TaskHandle;
osThreadId My_50ms_TaskHandle;
osThreadId My_DiagCheckHandle;
osThreadId my_AlarmControlHandle;
osMessageQId Queue_EEPROM_readHandle;
osMessageQId Queue_EEPROM_writeHandle;
osMessageQId Queue_error_snapshot_dumpHandle;
osMessageQId Queue_diagnostic_snapshot_dumpHandle;
osTimerId My_Timer_ENC_ButtonHandle;
osTimerId My_Timer_carWaterTempValueCheckHandle;
osTimerId My_Timer_carOilTempValueCheckHandle;
osTimerId My_Timer_carOilAnalogPressureValueCheckHandle;
osTimerId My_Timer_carMainBattVoltageValueCheckHandle;
osTimerId My_Timer_carAuxBattVoltageValueCheckHandle;
osTimerId My_Timer_carFuelLevelValueCheckHandle;
osTimerId My_Timer_board3V3VoltageValueCheckHandle;
osTimerId My_Timer_board5VVoltageValueCheckHandle;
osTimerId My_Timer_boardVinVoltageValueCheckHandle;
osTimerId My_Timer_board3V3TempValueCheckHandle;
osTimerId My_Timer_board5VTempValueCheckHandle;
osTimerId My_Timer_carOilBinaryPressureValueCheckHandle;
osTimerId My_Timer_BuzzerHandle;

void StartTask1000ms(void const * argument);
void StartTask500ms(void const * argument);
extern void StartTaskLCD(void const * argument);
extern void StartTaskGPS(void const * argument);
extern void StartTaskEEPROM(void const * argument);
extern void StartTaskDumpToEEPROM(void const * argument);
void StartTaskDumpToSDCard(void const * argument);
void StartTask250ms(void const * argument);
void StartTask50ms(void const * argument);
extern void StartTaskDiagCheck(void const * argument);
extern void StartTaskAlarmControl(void const * argument);
void ENC_Button_LongPress_Callback(void const * argument);
extern void Timer_carWaterTempValueCheck(void const * argument);
extern void Timer_carOilTempValueCheck(void const * argument);
extern void Timer_carOilAnalogPressureValueCheck(void const * argument);
extern void Timer_carMainBattVoltageValueCheck(void const * argument);
extern void Timer_carAuxBattVoltageValueCheck(void const * argument);
extern void Timer_carFuelLevelValueCheck(void const * argument);
extern void Timer_board3V3VoltageValueCheck(void const * argument);
extern void Timer_board5VVoltageValueCheck(void const * argument);
extern void Timer_boardVinVoltageValueCheck(void const * argument);
extern void Timer_board3V3TempValueCheck(void const * argument);
extern void Timer_board5VTempValueCheck(void const * argument);
extern void Timer_carOilBinaryPressureValueCheck(void const * argument);
extern void Timer_Buzzer(void const * argument);

extern void MX_USB_DEVICE_Init(void);
void MX_FREERTOS_Init(void); /* (MISRA C 2004 rule 8.1) */

/* GetIdleTaskMemory prototype (linked to static allocation support) */
void vApplicationGetIdleTaskMemory( StaticTask_t **ppxIdleTaskTCBBuffer, StackType_t **ppxIdleTaskStackBuffer, uint32_t *pulIdleTaskStackSize );

/* GetTimerTaskMemory prototype (linked to static allocation support) */
void vApplicationGetTimerTaskMemory( StaticTask_t **ppxTimerTaskTCBBuffer, StackType_t **ppxTimerTaskStackBuffer, uint32_t *pulTimerTaskStackSize );

/* Hook prototypes */
void configureTimerForRunTimeStats(void);
unsigned long getRunTimeCounterValue(void);
void vApplicationStackOverflowHook(TaskHandle_t xTask, signed char *pcTaskName);
void vApplicationMallocFailedHook(void);

/* USER CODE BEGIN 1 */
/* Functions needed when configGENERATE_RUN_TIME_STATS is on */
__weak void configureTimerForRunTimeStats(void)
{	/* FOR DEBUGGING */
#ifdef RUNTIME_STATS_TIMER_CONFIG
	HAL_TIM_Base_Start_IT(&htim7);
#endif
}

__weak unsigned long getRunTimeCounterValue(void)
{	/* FOR DEBUGGING */
#ifdef RUNTIME_STATS_TIMER_CONFIG
	return Tim7_Counter_100us;
#endif
}
/* USER CODE END 1 */

/* USER CODE BEGIN 4 */
__weak void vApplicationStackOverflowHook(TaskHandle_t xTask, signed char *pcTaskName)
{
   /* Run time stack overflow checking is performed if
   configCHECK_FOR_STACK_OVERFLOW is defined to 1 or 2. This hook function is
   called if a stack overflow is detected. */
	while(1)
	{
		HAL_GPIO_TogglePin(LED_3_GPIO_Port, LED_3_Pin);
		HAL_GPIO_TogglePin(LED_4_GPIO_Port, LED_4_Pin);
		HAL_GPIO_TogglePin(LED_5_GPIO_Port, LED_5_Pin);
		HAL_GPIO_TogglePin(LED_6_GPIO_Port, LED_6_Pin);
		HAL_Delay(500);
	}
}
/* USER CODE END 4 */

/* USER CODE BEGIN 5 */
__weak void vApplicationMallocFailedHook(void)
{
   /* vApplicationMallocFailedHook() will only be called if
   configUSE_MALLOC_FAILED_HOOK is set to 1 in FreeRTOSConfig.h. It is a hook
   function that will get called if a call to pvPortMalloc() fails.
   pvPortMalloc() is called internally by the kernel whenever a task, queue,
   timer or semaphore is created. It is also called by various parts of the
   demo application. If heap_1.c or heap_2.c are used, then the size of the
   heap available to pvPortMalloc() is defined by configTOTAL_HEAP_SIZE in
   FreeRTOSConfig.h, and the xPortGetFreeHeapSize() API function can be used
   to query the size of free heap space that remains (although it does not
   provide information on how the remaining heap might be fragmented). */
	while(1)
	{
		HAL_GPIO_TogglePin(LED_3_GPIO_Port, LED_3_Pin);
		HAL_GPIO_TogglePin(LED_4_GPIO_Port, LED_4_Pin);
		HAL_GPIO_TogglePin(LED_5_GPIO_Port, LED_5_Pin);
		HAL_GPIO_TogglePin(LED_6_GPIO_Port, LED_6_Pin);
		HAL_Delay(500);
	}
}
/* USER CODE END 5 */

/* USER CODE BEGIN GET_IDLE_TASK_MEMORY */
static StaticTask_t xIdleTaskTCBBuffer;
static StackType_t xIdleStack[configMINIMAL_STACK_SIZE];

void vApplicationGetIdleTaskMemory(StaticTask_t **ppxIdleTaskTCBBuffer,
		StackType_t **ppxIdleTaskStackBuffer, uint32_t *pulIdleTaskStackSize)
{
	*ppxIdleTaskTCBBuffer = &xIdleTaskTCBBuffer;
	*ppxIdleTaskStackBuffer = &xIdleStack[0];
	*pulIdleTaskStackSize = configMINIMAL_STACK_SIZE;
	/* place for user code */
}
/* USER CODE END GET_IDLE_TASK_MEMORY */

/* USER CODE BEGIN GET_TIMER_TASK_MEMORY */
static StaticTask_t xTimerTaskTCBBuffer;
static StackType_t xTimerStack[configTIMER_TASK_STACK_DEPTH];

void vApplicationGetTimerTaskMemory( StaticTask_t **ppxTimerTaskTCBBuffer, StackType_t **ppxTimerTaskStackBuffer, uint32_t *pulTimerTaskStackSize )
{
  *ppxTimerTaskTCBBuffer = &xTimerTaskTCBBuffer;
  *ppxTimerTaskStackBuffer = &xTimerStack[0];
  *pulTimerTaskStackSize = configTIMER_TASK_STACK_DEPTH;
  /* place for user code */
}
/* USER CODE END GET_TIMER_TASK_MEMORY */

void MX_FREERTOS_Init(void) {

  /* Create the timer(s) */
  /* definition and creation of My_Timer_ENC_Button */
  osTimerDef(My_Timer_ENC_Button, ENC_Button_LongPress_Callback);
  My_Timer_ENC_ButtonHandle = osTimerCreate(osTimer(My_Timer_ENC_Button), osTimerOnce, NULL);

  /* definition and creation of My_Timer_carWaterTempValueCheck */
  osTimerDef(My_Timer_carWaterTempValueCheck, Timer_carWaterTempValueCheck);
  My_Timer_carWaterTempValueCheckHandle = osTimerCreate(osTimer(My_Timer_carWaterTempValueCheck), osTimerOnce, NULL);

  /* definition and creation of My_Timer_carOilTempValueCheck */
  osTimerDef(My_Timer_carOilTempValueCheck, Timer_carOilTempValueCheck);
  My_Timer_carOilTempValueCheckHandle = osTimerCreate(osTimer(My_Timer_carOilTempValueCheck), osTimerOnce, NULL);

  /* definition and creation of My_Timer_carOilAnalogPressureValueCheck */
  osTimerDef(My_Timer_carOilAnalogPressureValueCheck, Timer_carOilAnalogPressureValueCheck);
  My_Timer_carOilAnalogPressureValueCheckHandle = osTimerCreate(osTimer(My_Timer_carOilAnalogPressureValueCheck), osTimerOnce, NULL);

  /* definition and creation of My_Timer_carMainBattVoltageValueCheck */
  osTimerDef(My_Timer_carMainBattVoltageValueCheck, Timer_carMainBattVoltageValueCheck);
  My_Timer_carMainBattVoltageValueCheckHandle = osTimerCreate(osTimer(My_Timer_carMainBattVoltageValueCheck), osTimerOnce, NULL);

  /* definition and creation of My_Timer_carAuxBattVoltageValueCheck */
  osTimerDef(My_Timer_carAuxBattVoltageValueCheck, Timer_carAuxBattVoltageValueCheck);
  My_Timer_carAuxBattVoltageValueCheckHandle = osTimerCreate(osTimer(My_Timer_carAuxBattVoltageValueCheck), osTimerOnce, NULL);

  /* definition and creation of My_Timer_carFuelLevelValueCheck */
  osTimerDef(My_Timer_carFuelLevelValueCheck, Timer_carFuelLevelValueCheck);
  My_Timer_carFuelLevelValueCheckHandle = osTimerCreate(osTimer(My_Timer_carFuelLevelValueCheck), osTimerOnce, NULL);

  /* definition and creation of My_Timer_board3V3VoltageValueCheck */
  osTimerDef(My_Timer_board3V3VoltageValueCheck, Timer_board3V3VoltageValueCheck);
  My_Timer_board3V3VoltageValueCheckHandle = osTimerCreate(osTimer(My_Timer_board3V3VoltageValueCheck), osTimerOnce, NULL);

  /* definition and creation of My_Timer_board5VVoltageValueCheck */
  osTimerDef(My_Timer_board5VVoltageValueCheck, Timer_board5VVoltageValueCheck);
  My_Timer_board5VVoltageValueCheckHandle = osTimerCreate(osTimer(My_Timer_board5VVoltageValueCheck), osTimerOnce, NULL);

  /* definition and creation of My_Timer_boardVinVoltageValueCheck */
  osTimerDef(My_Timer_boardVinVoltageValueCheck, Timer_boardVinVoltageValueCheck);
  My_Timer_boardVinVoltageValueCheckHandle = osTimerCreate(osTimer(My_Timer_boardVinVoltageValueCheck), osTimerOnce, NULL);

  /* definition and creation of My_Timer_board3V3TempValueCheck */
  osTimerDef(My_Timer_board3V3TempValueCheck, Timer_board3V3TempValueCheck);
  My_Timer_board3V3TempValueCheckHandle = osTimerCreate(osTimer(My_Timer_board3V3TempValueCheck), osTimerOnce, NULL);

  /* definition and creation of My_Timer_board5VTempValueCheck */
  osTimerDef(My_Timer_board5VTempValueCheck, Timer_board5VTempValueCheck);
  My_Timer_board5VTempValueCheckHandle = osTimerCreate(osTimer(My_Timer_board5VTempValueCheck), osTimerOnce, NULL);

  /* definition and creation of My_Timer_carOilBinaryPressureValueCheck */
  osTimerDef(My_Timer_carOilBinaryPressureValueCheck, Timer_carOilBinaryPressureValueCheck);
  My_Timer_carOilBinaryPressureValueCheckHandle = osTimerCreate(osTimer(My_Timer_carOilBinaryPressureValueCheck), osTimerOnce, NULL);

  /* definition and creation of My_Timer_Buzzer */
  osTimerDef(My_Timer_Buzzer, Timer_Buzzer);
  My_Timer_BuzzerHandle = osTimerCreate(osTimer(My_Timer_Buzzer), osTimerOnce, NULL);

  /* Create the queue(s) */
  /* definition and creation of Queue_EEPROM_read */
  osMessageQDef(Queue_EEPROM_read, 5, EEPROM_data_struct);
  Queue_EEPROM_readHandle = osMessageCreate(osMessageQ(Queue_EEPROM_read), NULL);

  /* definition and creation of Queue_EEPROM_write */
  osMessageQDef(Queue_EEPROM_write, 5, EEPROM_data_struct);
  Queue_EEPROM_writeHandle = osMessageCreate(osMessageQ(Queue_EEPROM_write), NULL);

  /* definition and creation of Queue_error_snapshot_dump */
  osMessageQDef(Queue_error_snapshot_dump, 5, Error_Code);
  Queue_error_snapshot_dumpHandle = osMessageCreate(osMessageQ(Queue_error_snapshot_dump), NULL);

  /* definition and creation of Queue_diagnostic_snapshot_dump */
  osMessageQDef(Queue_diagnostic_snapshot_dump, 5, Diagnostic_Snapshot_struct);
  Queue_diagnostic_snapshot_dumpHandle = osMessageCreate(osMessageQ(Queue_diagnostic_snapshot_dump), NULL);

  /* Create the thread(s) */
  /* definition and creation of My_1000ms_Task */
  osThreadDef(My_1000ms_Task, StartTask1000ms, osPriorityNormal, 0, 256);
  My_1000ms_TaskHandle = osThreadCreate(osThread(My_1000ms_Task), NULL);

  /* definition and creation of My_500ms_Task */
  osThreadDef(My_500ms_Task, StartTask500ms, osPriorityNormal, 0, 128);
  My_500ms_TaskHandle = osThreadCreate(osThread(My_500ms_Task), NULL);

  /* definition and creation of My_LCD_Task */
  osThreadDef(My_LCD_Task, StartTaskLCD, osPriorityNormal, 0, 512);
  My_LCD_TaskHandle = osThreadCreate(osThread(My_LCD_Task), NULL);

  /* definition and creation of My_GPS_Task */
  osThreadDef(My_GPS_Task, StartTaskGPS, osPriorityNormal, 0, 128);
  My_GPS_TaskHandle = osThreadCreate(osThread(My_GPS_Task), NULL);

  /* definition and creation of My_EEPROM_Task */
  osThreadDef(My_EEPROM_Task, StartTaskEEPROM, osPriorityHigh, 0, 128);
  My_EEPROM_TaskHandle = osThreadCreate(osThread(My_EEPROM_Task), NULL);

  /* definition and creation of My_DumpToEEPROM */
  osThreadDef(My_DumpToEEPROM, StartTaskDumpToEEPROM, osPriorityBelowNormal, 0, 128);
  My_DumpToEEPROMHandle = osThreadCreate(osThread(My_DumpToEEPROM), NULL);

  /* definition and creation of My_DumpToSDCard */
  osThreadDef(My_DumpToSDCard, StartTaskDumpToSDCard, osPriorityBelowNormal, 0, 1024);
  My_DumpToSDCardHandle = osThreadCreate(osThread(My_DumpToSDCard), NULL);

  /* definition and creation of My_250ms_Task */
  osThreadDef(My_250ms_Task, StartTask250ms, osPriorityIdle, 0, 512);
  My_250ms_TaskHandle = osThreadCreate(osThread(My_250ms_Task), NULL);

  /* definition and creation of My_50ms_Task */
  osThreadDef(My_50ms_Task, StartTask50ms, osPriorityIdle, 0, 128);
  My_50ms_TaskHandle = osThreadCreate(osThread(My_50ms_Task), NULL);

  /* definition and creation of My_DiagCheck */
  osThreadDef(My_DiagCheck, StartTaskDiagCheck, osPriorityAboveNormal, 0, 256);
  My_DiagCheckHandle = osThreadCreate(osThread(My_DiagCheck), NULL);

  /* definition and creation of my_AlarmControl */
  osThreadDef(my_AlarmControl, StartTaskAlarmControl, osPriorityIdle, 0, 256);
  my_AlarmControlHandle = osThreadCreate(osThread(my_AlarmControl), NULL);

}

void StartTask1000ms(void const * argument)
{
  /* init code for USB_DEVICE */
  MX_USB_DEVICE_Init();
  /* USER CODE BEGIN StartTask1000ms */

	TickType_t xLastWakeTime;
	const TickType_t xFrequency = MY_TASK_1000_MS_TIME_PERIOD;
	Error_Code error = NO_ERROR;

	static uint8_t totalMileageMessage[7] = "";
	static uint8_t tripMileageMessage[8] = "";
	totalMileageForLCD.messageHandler = totalMileageMessage;
	tripMileageForLCD.messageHandler = tripMileageMessage;

	static uint8_t temperature3V3DCDC_message[6] = {SPACE_IN_ASCII};
	static uint8_t temperature5VDCDC_message[6] = {SPACE_IN_ASCII};
	temperature3V3DCDCForLCD.messageHandler = temperature3V3DCDC_message;
	temperature5VDCDCForLCD.messageHandler = temperature5VDCDC_message;

	static uint8_t voltage3V3_message[5] = {SPACE_IN_ASCII};
	static uint8_t voltage5V_message[5] = {SPACE_IN_ASCII};
	static uint8_t voltageIn_message[6] = {SPACE_IN_ASCII};
	voltage3V3ForLCD.messageHandler = voltage3V3_message;
	voltage5VForLCD.messageHandler = voltage5V_message;
	voltageInForLCD.messageHandler = voltageIn_message;

	xLastWakeTime = xTaskGetTickCount();

	/* Infinite loop */
	/* * * * * * * * * * * * * * * * * * * * * * * * * * * * * * * * * * * * */
	for (;;)
	{
		error = calculate_NTC_temperature(&temperature5VDCDC, ADC3Measures[3]/*NTC near 5V stabilizer*/, &NTC);

		if(NO_ERROR != error)
		{
			my_error_handler(error);
		}
		else
		{
			temperature5VDCDCForLCD.messageReadyFLAG = FALSE;
			snprintf((char*)temperature5VDCDCForLCD.messageHandler, 6, "%" PRIi16 "%cC", (uint16_t)temperature5VDCDC, DEGREE_SYMBOL_LCD);
			temperature5VDCDCForLCD.size = strlen((char*)temperature5VDCDCForLCD.messageHandler);
			temperature5VDCDCForLCD.messageReadyFLAG = TRUE;
		}

		error = calculate_NTC_temperature(&temperature3V3DCDC, ADC3Measures[2]/*NTC near DC/DC*/, &NTC);

		if(NO_ERROR != error)
		{
			my_error_handler(error);
		}
		else
		{
			temperature3V3DCDCForLCD.messageReadyFLAG = FALSE;
			snprintf((char*)temperature3V3DCDCForLCD.messageHandler, 6, "%" PRIi16 "%cC", (uint16_t)temperature3V3DCDC, DEGREE_SYMBOL_LCD);
			temperature3V3DCDCForLCD.size = strlen((char*)temperature3V3DCDCForLCD.messageHandler);
			temperature3V3DCDCForLCD.messageReadyFLAG = TRUE;
		}

		error = calculate_voltage(&voltageIn, ADC3Measures[0]/*Vin*/, MEASURE_VIN_VOLTAGE_DIVIDER);

		if(NO_ERROR != error)
		{
			my_error_handler(error);
		}
		else
		{
			voltageInForLCD.messageReadyFLAG = FALSE;
			snprintf((char*)voltageInForLCD.messageHandler, 7, "%01" PRIu16 ".%02" PRIu16 "V", (uint16_t)voltageIn, (uint16_t)(voltageIn*100)%100);
			voltageInForLCD.size = strlen((char*)voltageInForLCD.messageHandler);
			voltageInForLCD.messageReadyFLAG = TRUE;
		}

		error = calculate_voltage(&voltage5V, ADC3Measures[1]/*5V*/, MEASURE_5V_VOLTAGE_DIVIDER);

		if(NO_ERROR != error)
		{
			my_error_handler(error);
		}
		else
		{
			voltage5VForLCD.messageReadyFLAG = FALSE;
			snprintf((char*)voltage5VForLCD.messageHandler, 6, "%01" PRIu16 ".%02" PRIi16 "V", (uint16_t)voltage5V, (uint16_t)(voltage5V*100)%100);
			voltage5VForLCD.size = strlen((char*)voltage5VForLCD.messageHandler);
			voltage5VForLCD.messageReadyFLAG = TRUE;;
		}

		totalMileageForLCD.messageReadyFLAG = FALSE;
		snprintf((char*)totalMileageForLCD.messageHandler, 6, "%01" PRIu32, CAR_mileage.totalMileage);
		totalMileageForLCD.size = strlen((char*)totalMileageForLCD.messageHandler);
		totalMileageForLCD.messageReadyFLAG = TRUE;

		tripMileageForLCD.messageReadyFLAG = FALSE;
		snprintf((char*)tripMileageForLCD.messageHandler, 5, "%01" PRIu32 ".%01" PRIu32, (CAR_mileage.tripMileage/10), (CAR_mileage.tripMileage)%10);
		tripMileageForLCD.size = strlen((char*)tripMileageForLCD.messageHandler);
		tripMileageForLCD.messageReadyFLAG = TRUE;

		vTaskDelayUntil(&xLastWakeTime, xFrequency);
	}
	/* * * * * * * * * * * * * * * * * * * * * * * * * * * * * * * * * * * * */

  /* USER CODE END StartTask1000ms */
}

void StartTask500ms(void const * argument)
{
  /* USER CODE BEGIN StartTask500ms */

	TickType_t xLastWakeTime;
	const TickType_t xFrequency = MY_TASK_500_MS_TIME_PERIOD;

	xLastWakeTime = xTaskGetTickCount();

	/* Infinite loop */
	/* * * * * * * * * * * * * * * * * * * * * * * * * * * * * * * * * * * * */
	for (;;)
	{
		HAL_GPIO_TogglePin(LED_2_GPIO_Port, LED_2_Pin);

		vTaskDelayUntil(&xLastWakeTime, xFrequency);
	}
	/* * * * * * * * * * * * * * * * * * * * * * * * * * * * * * * * * * * * */

  /* USER CODE END StartTask500ms */
}

void StartTaskDumpToSDCard(void const * argument)
{
  /* USER CODE BEGIN StartTaskDumpToSDCard */

	TickType_t xLastWakeTime;
	const TickType_t xFrequency = MY_DUMP_TO_SDCARD_TASK_TIME_PERIOD;
	Error_Code error = NO_ERROR;

	MX_USB_DEVICE_Init();

	FRESULT result = FR_OK;

	char ReadBuffer[100] = "";
	uint32_t NoOfReadBytes = 0;

	/* Check if SD card is ready to be used */
	while(HAL_SD_STATE_READY != hsd.State)
	{
		vTaskDelay((TickType_t)100);
	}

	result = BSP_SD_Init();

	if(FR_OK == result)
	{
		result = f_mount(&SDFatFS, "", 1);
	}
	if(FR_OK == result)
	{
	result = f_open(&SDFile, "test.txt", FA_READ);
	}
	if(FR_OK == result)
	{
	result = f_read(&SDFile, ReadBuffer, 20, (UINT*)&NoOfReadBytes);
	}
	if(FR_OK == result)
	{
	result = f_close(&SDFile);
	}

	if(TRUE != compare_two_strings(ReadBuffer, TEST_MESSAGE_FOR_CHECK, 0u, 20u))
	{
		error = SDCARD__INITIAL_READ_FAILED;
		my_error_handler(error);

		/* Stop the task now, because if the card is not read correctly then do not proceed! */
		vTaskSuspend(My_DumpToSDCardHandle);
	}

	error = copy_str_to_buffer(ReadBuffer, (char*)TEMPBUFF, 0, 20);
	tuBylemFLAG = 1;

	xLastWakeTime = xTaskGetTickCount();

  /* Infinite loop */
  for(;;)
  {
	  vTaskDelayUntil(&xLastWakeTime, xFrequency);
  }
  /* USER CODE END StartTaskDumpToSDCard */
}

void StartTask250ms(void const * argument)
{
  /* USER CODE BEGIN StartTask250ms */

	TickType_t xLastWakeTime;
	const TickType_t xFrequency = MY_TASK_250_MS_TIME_PERIOD;
	Error_Code error = NO_ERROR;
	uint8_t firstFewRuns = 0u;

	/* Stop My_DiagCheck Task because measurements are not ready yet! */
	vTaskSuspend(My_DiagCheckHandle);

	/* For calculating the engine parameters (counting the mean value) */
	static volatile carTemperature_type EngineWaterTemperatureTable[NO_OF_ENGINE_WATER_TEMP_MEASUREMENTS_ADDED] = {0};
	static volatile carTemperature_type EngineWaterTemperatureMovingAverage[NO_OF_ENGINE_WATER_TEMP_MEASUREMENTS_ADDED] = {0};
	static uint8_t i_waterTemp = 0;
	static carTemperature_type tempEngineWaterTemp = 0.0;
	carTemperature_type waterTemperatureValue_beforeMovingAverage = 0.0;
	static uint8_t waterTemperatureValueMessage[4] = "";
	waterTemperatureValueForLCD.messageHandler = waterTemperatureValueMessage;

	static volatile carTemperature_type EngineOilTemperatureTable[NO_OF_ENGINE_OIL_TEMP_MEASUREMENTS_ADDED] = {0};
	static volatile carTemperature_type EngineOilTemperatureTableMovingAverage[NO_OF_ENGINE_OIL_TEMP_MEASUREMENTS_ADDED] = {0};
	static uint8_t i_oilTemp = 0;
	static carTemperature_type tempEngineOilTemp = 0.0;
	carTemperature_type oilTemperatureValue_beforeMovingAverage = 0.0;
	static uint8_t oilTemperatureValueMessage[4] = "";
	oilTemperatureValueForLCD.messageHandler = oilTemperatureValueMessage;

#ifdef OIL_PRESSURE_ANALOG_SENSOR
	static volatile carOilAnalogPressure_type EngineOilPressureTable[NO_OF_ENGINE_OIL_PRESSURE_MEASUREMENTS_ADDED] = {0};
//	static volatile float EngineOilPressureTableMovingAverage[NO_OF_ENGINE_OIL_PRESSURE_MEASUREMENTS_ADDED] = {0};
	static uint8_t i_oilPressure = 0;
	static carOilAnalogPressure_type tempEngineOilPressure = 0.0;
	static uint8_t oilPressureValueMessage[4] = "";
	oilPressureValueForLCD.messageHandler = oilPressureValueMessage;
#endif

#ifdef OIL_PRESSURE_BINARY_SENSOR
	static uint8_t oilPressureValueBinaryMessage[4] = "";	//OK, NOK
	oilPressureValueBinaryForLCD.messageHandler = oilPressureValueBinaryMessage;
#endif

	static volatile carVoltage_type MainBatteryVoltageValueTable[NO_OF_MAIN_BATTERY_VOLTAGE_MEASUREMENTS_ADDED] = {0};
//	static volatile float MainBatteryVoltageValueTableMovingAverage[NO_OF_MAIN_BATTERY_VOLTAGE_MEASUREMENTS_ADDED] = {0};
	static uint8_t i_mainBateryVoltage = 0;
	static carVoltage_type tempMainBatteryVoltage = 0.0;
	static uint8_t mainBatteryVoltageValueMessage[6] = "";
	mainBatteryVoltageValueForLCD.messageHandler = mainBatteryVoltageValueMessage;

	static volatile carVoltage_type AuxiliaryBatteryVoltageValueTable[NO_OF_AUXILIARY_BATTERY_VOLTAGE_MEASUREMENTS_ADDED] = {0};
//	static volatile float AuxiliaryBatteryVoltageValueTableMovingAverage[NO_OF_AUXILIARY_BATTERY_VOLTAGE_MEASUREMENTS_ADDED] = {0};
	static uint8_t i_auxBatteryVoltage = 0;
	static carVoltage_type tempAuxBatteryVoltage = 0.0;
	static uint8_t auxiliaryBatteryVoltageValueMessage[6] = "";
	auxiliaryBatteryVoltageValueForLCD.messageHandler = auxiliaryBatteryVoltageValueMessage;

	static volatile cafFuelLevel_type FuelLevelValueTable[NO_OF_FUEL_LEVEL_MEASUREMENTS_ADDED] = {0};
	static volatile cafFuelLevel_type FuelLevelValueTableMovingAverage[NO_OF_FUEL_LEVEL_MEASUREMENTS_ADDED] = {0};
	static uint8_t i_fuelLevel = 0;
	static cafFuelLevel_type tempFuelLevel = 0.0;
	cafFuelLevel_type fuelLevelValue_beforeMovingAverage = 0.0;
	static uint8_t fuelLevelValueMessage[3] = "";
	fuelLevelValueForLCD.messageHandler = fuelLevelValueMessage;

	xLastWakeTime = xTaskGetTickCount();

	/* Infinite loop */
	for (;;)
	{
		/* Water Temperature Value measurement from LM35 */
		if(NO_OF_ENGINE_WATER_TEMP_MEASUREMENTS_ADDED > i_waterTemp)
		{
			error = calculate_LM35_temperature((float*)&tempEngineWaterTemp, ADC1Measures[0]);

			waterTemperatureValue = tempEngineWaterTemp;

			waterTemperatureValueForLCD.messageReadyFLAG = FALSE;
			snprintf((char*)waterTemperatureValueForLCD.messageHandler, 4, "%3" PRIu16, (uint16_t)waterTemperatureValue);
			waterTemperatureValueForLCD.size = strlen((char*)waterTemperatureValueForLCD.messageHandler);
			waterTemperatureValueForLCD.messageReadyFLAG = TRUE;

			tempEngineWaterTemp = 0;
		}

		if(NO_ERROR != error)
		{
		  my_error_handler(error);
		}

		/* Oil Temperature Value measurement */
		if(NO_OF_ENGINE_OIL_TEMP_MEASUREMENTS_ADDED > i_oilTemp)
		{
			error = calculate_LM35_temperature((float*)&(EngineOilTemperatureTable[i_oilTemp]), ADC1Measures[0]);
			tempEngineOilTemp += EngineOilTemperatureTable[i_oilTemp];
			i_oilTemp += 1;
		}
		else
		{
			oilTemperatureValue_beforeMovingAverage = tempEngineOilTemp / NO_OF_ENGINE_OIL_TEMP_MEASUREMENTS_ADDED;
			EngineOilTemperatureTableMovingAverage[NO_OF_ENGINE_OIL_TEMP_MEASUREMENTS_ADDED-1] = oilTemperatureValue_beforeMovingAverage;
			tempEngineOilTemp = oilTemperatureValue_beforeMovingAverage;

			for(uint8_t j = 0; j< (NO_OF_ENGINE_OIL_TEMP_MEASUREMENTS_ADDED - 1); ++j)
			{
				EngineOilTemperatureTableMovingAverage[j] = EngineOilTemperatureTableMovingAverage[j+1];
				tempEngineOilTemp += EngineOilTemperatureTableMovingAverage[j];
			}

			oilTemperatureValue = tempEngineOilTemp / NO_OF_ENGINE_OIL_TEMP_MEASUREMENTS_ADDED;

			oilTemperatureValueForLCD.messageReadyFLAG = FALSE;
			snprintf((char*)oilTemperatureValueForLCD.messageHandler, 4, "%3" PRIu16, (uint16_t)oilTemperatureValue);
			oilTemperatureValueForLCD.size = strlen((char*)oilTemperatureValueForLCD.messageHandler);
			oilTemperatureValueForLCD.messageReadyFLAG = TRUE;

			tempEngineOilTemp = 0;
			i_oilTemp = 0;
		}

		if(NO_ERROR != error)
		{
		  my_error_handler(error);
		}

		/* Oil Pressure Value measurement */
#ifdef OIL_PRESSURE_ANALOG_SENSOR
		if(NO_OF_ENGINE_OIL_PRESSURE_MEASUREMENTS_ADDED > i_oilPressure)
		{
			error = calculate_EngineOilPressure((float*)&(EngineOilPressureTable[i_oilPressure]), ADC1Measures[0]);
			tempEngineOilPressure += EngineOilPressureTable[i_oilPressure];
			i_oilPressure += 1;
		}
		else
		{
			oilPressureValue = tempEngineOilPressure / NO_OF_ENGINE_OIL_PRESSURE_MEASUREMENTS_ADDED;

			oilPressureValueForLCD.messageReadyFLAG = FALSE;
			snprintf((char*)oilPressureValueForLCD.messageHandler, 4, "%01" PRIu16 ".%01" PRIu16, (uint16_t)oilPressureValue, (uint16_t)(oilPressureValue*10)%10);
			oilPressureValueForLCD.size = strlen((char*)oilPressureValueForLCD.messageHandler);
			oilPressureValueForLCD.messageReadyFLAG = TRUE;

			tempEngineOilPressure = 0;
			i_oilPressure = 0;
		}
#endif

#ifdef OIL_PRESSURE_BINARY_SENSOR
		if(GPIO_PIN_RESET == HAL_GPIO_ReadPin(GPIO_PORT_OIL_PRESSURE_SENSOR, GPIO_PIN_OIL_PRESSURE_SENSOR))
		{
			oilPressureValueBinary = OK;
			oilPressureValueBinaryForLCD.messageReadyFLAG = FALSE;
			snprintf((char*)oilPressureValueBinaryForLCD.messageHandler, 4, "OK");
			oilPressureValueBinaryForLCD.size = strlen((char*)oilPressureValueForLCD.messageHandler);
			oilPressureValueBinaryForLCD.messageReadyFLAG = TRUE;
		}
		else
		{
			oilPressureValueBinary = NOK;
			oilPressureValueBinaryForLCD.messageReadyFLAG = FALSE;
			snprintf((char*)oilPressureValueBinaryForLCD.messageHandler, 4, "NOK");
			oilPressureValueBinaryForLCD.size = strlen((char*)oilPressureValueForLCD.messageHandler);
			oilPressureValueBinaryForLCD.messageReadyFLAG = TRUE;
		}
#endif

		if(NO_ERROR != error)
		{
		  my_error_handler(error);
		}

		/* Main Battery Voltage Value measurement */
		if(NO_OF_MAIN_BATTERY_VOLTAGE_MEASUREMENTS_ADDED > i_mainBateryVoltage)
		{
			for(uint8_t j = 1; j< (NO_OF_MAIN_BATTERY_VOLTAGE_MEASUREMENTS_ADDED); ++j)
			{
				MainBatteryVoltageValueTable[j] = MainBatteryVoltageValueTable[j-1];
				tempMainBatteryVoltage += MainBatteryVoltageValueTable[j];
			}

			error = calculate_voltage((float*)&(MainBatteryVoltageValueTable[0u]), ADC1Measures[0], MAIN_BATTERY_VOLTAGE_DIVIDER);
			tempMainBatteryVoltage += MainBatteryVoltageValueTable[0u];
			mainBatteryVoltageValue = tempMainBatteryVoltage / NO_OF_MAIN_BATTERY_VOLTAGE_MEASUREMENTS_ADDED;

			mainBatteryVoltageValueForLCD.messageReadyFLAG = FALSE;
			snprintf((char*)mainBatteryVoltageValueForLCD.messageHandler, 6, "%02" PRIu16 ".%02" PRIu16, (uint16_t)mainBatteryVoltageValue, (uint16_t)(mainBatteryVoltageValue*100)%100);
			mainBatteryVoltageValueForLCD.size = strlen((char*)mainBatteryVoltageValueForLCD.messageHandler);
			mainBatteryVoltageValueForLCD.messageReadyFLAG = TRUE;

			i_mainBateryVoltage += 1;
			tempMainBatteryVoltage = 0;
		}
		else
		{
			tempMainBatteryVoltage = 0;
			i_mainBateryVoltage = 0;
		}

		if(NO_ERROR != error)
		{
		  my_error_handler(error);
		}

		/* Auxiliary Battery Voltage Value measurement */
		if(NO_OF_AUXILIARY_BATTERY_VOLTAGE_MEASUREMENTS_ADDED > i_auxBatteryVoltage)
		{
			for(uint8_t j = 1; j< (NO_OF_AUXILIARY_BATTERY_VOLTAGE_MEASUREMENTS_ADDED); ++j)
			{
				AuxiliaryBatteryVoltageValueTable[j] = AuxiliaryBatteryVoltageValueTable[j-1];
				tempAuxBatteryVoltage += AuxiliaryBatteryVoltageValueTable[j];
			}

			error = calculate_voltage((float*)&(AuxiliaryBatteryVoltageValueTable[0u]), ADC1Measures[0], AUXILIARY_BATTERY_VOLTAGE_DIVIDER);
			tempAuxBatteryVoltage += AuxiliaryBatteryVoltageValueTable[0u];
			auxiliaryBatteryVoltageValue = tempAuxBatteryVoltage / NO_OF_AUXILIARY_BATTERY_VOLTAGE_MEASUREMENTS_ADDED;

			auxiliaryBatteryVoltageValueForLCD.messageReadyFLAG = FALSE;
			snprintf((char*)auxiliaryBatteryVoltageValueForLCD.messageHandler, 6, "%02" PRIu16 ".%02" PRIu16, (uint16_t)auxiliaryBatteryVoltageValue, (uint16_t)(auxiliaryBatteryVoltageValue*100)%100);
			auxiliaryBatteryVoltageValueForLCD.size = strlen((char*)auxiliaryBatteryVoltageValueForLCD.messageHandler);
			auxiliaryBatteryVoltageValueForLCD.messageReadyFLAG = TRUE;

			i_auxBatteryVoltage += 1;
			tempAuxBatteryVoltage = 0;
		}
		else
		{
			tempAuxBatteryVoltage = 0;
			i_auxBatteryVoltage = 0;
		}

		if(NO_ERROR != error)
		{
		  my_error_handler(error);
		}

		/* Fuel Level Value measurement */
		if(NO_OF_FUEL_LEVEL_MEASUREMENTS_ADDED > i_fuelLevel)
		{
			error = calculate_fuelLevel((float*)&(FuelLevelValueTable[i_fuelLevel]), ADC1Measures[0]);
			tempFuelLevel += FuelLevelValueTable[i_fuelLevel];
			i_fuelLevel += 1;
		}
		else
		{
			fuelLevelValue_beforeMovingAverage = tempFuelLevel / NO_OF_FUEL_LEVEL_MEASUREMENTS_ADDED;
			FuelLevelValueTableMovingAverage[NO_OF_FUEL_LEVEL_MEASUREMENTS_ADDED-1] = fuelLevelValue_beforeMovingAverage;
			tempFuelLevel = fuelLevelValue_beforeMovingAverage;

			for(uint8_t j = 0; j< (NO_OF_FUEL_LEVEL_MEASUREMENTS_ADDED - 1); ++j)
			{
				FuelLevelValueTableMovingAverage[j] = FuelLevelValueTableMovingAverage[j+1];
				tempFuelLevel += FuelLevelValueTableMovingAverage[j];
			}

			fuelLevelValue = tempFuelLevel / NO_OF_FUEL_LEVEL_MEASUREMENTS_ADDED;

			fuelLevelValueForLCD.messageReadyFLAG = FALSE;
			snprintf((char*)fuelLevelValueForLCD.messageHandler, 4, "%3" PRIu16, (uint16_t)fuelLevelValue);
			fuelLevelValueForLCD.size = strlen((char*)fuelLevelValueForLCD.messageHandler);
			fuelLevelValueForLCD.messageReadyFLAG = TRUE;

			tempFuelLevel = 0;
			i_fuelLevel = 0;
		}

		if(NO_ERROR != error)
		{
		  my_error_handler(error);
		}

		/* Release My_DiagCheck Task after some measurements first */
		(NUMBER_OF_MEASUREMENTS_BEFORE_DIAGNOSTIC <= firstFewRuns) ? vTaskResume(My_DiagCheckHandle) : ++firstFewRuns;

		vTaskDelayUntil(&xLastWakeTime, xFrequency);
	}
  /* USER CODE END StartTask250ms */
}

void StartTask50ms(void const * argument)
{
  /* USER CODE BEGIN StartTask50ms */
	TickType_t xLastWakeTime;
	const TickType_t xFrequency = MY_TASK_50_MS_TIME_PERIOD;

	volatile uint16_t TIM8CounterReadout = 0;
	static uint16_t previousCounterValue = 0;
	volatile int32_t tempDiff = 0;

	xLastWakeTime = xTaskGetTickCount();

  /* Infinite loop */
  for(;;)
  {
	  TIM8CounterReadout = __HAL_TIM_GET_COUNTER(&htim8);
	  tempDiff = TIM8CounterReadout - previousCounterValue;

	  if((4 <= tempDiff) || (-4 >= tempDiff))
	  {
		  tempDiff /= 4;
		  EncoderCounterDiff += (int8_t)tempDiff;
		  previousCounterValue = TIM8CounterReadout;
	  }

	  vTaskDelayUntil(&xLastWakeTime, xFrequency);
  }
  /* USER CODE END StartTask50ms */
}

/* ENC_Button_LongPress_Callback function */
void ENC_Button_LongPress_Callback(void const * argument)
{
  /* USER CODE BEGIN ENC_Button_LongPress_Callback */

	ENC_button.allFlags |= 0b00010110; /* Set 1st, 2nd, 3rd bit to 1 to
	 	 	 	 	 	 	 	 	indicate the long press on bits:
	 	 	 	 	 	 	 	 	longPressDetected,
	 	 	 	 	 	 	 	 	longPressDetectedForISR,
	 	 	 	 	 	 	 	 	longPressDetectedBuzzer */

  /* USER CODE END ENC_Button_LongPress_Callback */
}

/************************ (C) COPYRIGHT STMicroelectronics *****END OF FILE****/
